# STM32L4x2 register map
File version: 1.6
CPU: CM4 r1p0, little endian, no MPU, no FPU, 3 interrupt priority bits
Registers are 32-bit, read-write, reset 0x0 unless marked. A register's access mark holds for its fields unless they carry their own. Offsets are from the block's base; [hi:lo] are bit positions; {n}, {i} and the like mark numbered series.

## WWDG — System window watchdog
Base 0x40002C00
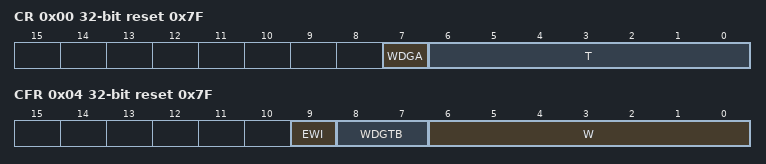
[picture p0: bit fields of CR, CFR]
0x00 CR reset 0x7F — Control register
  [7] WDGA — Activation bit
  [6:0] T — 7-bit counter (MSB to LSB)
0x04 CFR reset 0x7F — Configuration register
  [9] EWI — Early wakeup interrupt
  [8:7] WDGTB — Timer base
  [6:0] W — 7-bit window value
0x08 SR — Status register
  [0] EWIF — Early wakeup interrupt flag

## COMP — Comparator
Base 0x40010200
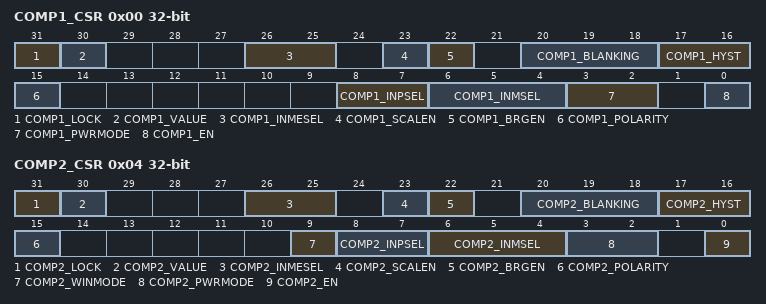
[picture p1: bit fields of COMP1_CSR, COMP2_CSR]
0x00 COMP1_CSR access per field — Comparator 1 control and status register
  [31] COMP1_LOCK wo — COMP1_CSR register lock bit
  [30] COMP1_VALUE ro — Comparator 1 output status bit
  [26:25] COMP1_INMESEL rw — comparator 1 input minus extended selection bits
  [23] COMP1_SCALEN rw — Voltage scaler enable bit
  [22] COMP1_BRGEN rw — Scaler bridge enable
  [20:18] COMP1_BLANKING rw — Comparator 1 blanking source selection bits
  [17:16] COMP1_HYST rw — Comparator 1 hysteresis selection bits
  [15] COMP1_POLARITY rw — Comparator 1 polarity selection bit
  [8:7] COMP1_INPSEL rw — Comparator1 input plus selection bit
  [6:4] COMP1_INMSEL rw — Comparator 1 Input Minus connection configuration bit
  [3:2] COMP1_PWRMODE rw — Power Mode of the comparator 1
  [0] COMP1_EN rw — Comparator 1 enable bit
0x04 COMP2_CSR access per field — Comparator 2 control and status register
  [31] COMP2_LOCK wo — COMP2_CSR register lock bit
  [30] COMP2_VALUE ro — Comparator 2 output status bit
  [26:25] COMP2_INMESEL rw — comparator 2 input minus extended selection bits
  [23] COMP2_SCALEN rw — Voltage scaler enable bit
  [22] COMP2_BRGEN rw — Scaler bridge enable
  [20:18] COMP2_BLANKING rw — Comparator 2 blanking source selection bits
  [17:16] COMP2_HYST rw — Comparator 2 hysteresis selection bits
  [15] COMP2_POLARITY rw — Comparator 2 polarity selection bit
  [9] COMP2_WINMODE rw — Windows mode selection bit
  [8:7] COMP2_INPSEL rw — Comparator 2 Input Plus connection configuration bit
  [6:4] COMP2_INMSEL rw — Comparator 2 Input Minus connection configuration bit
  [3:2] COMP2_PWRMODE rw — Power Mode of the comparator 2
  [0] COMP2_EN rw — Comparator 2 enable bit

## FIREWALL
Base 0x40011C00
0x00 CSSA — Code segment start address
  [23:8] ADD — code segment start address
0x04 CSL — Code segment length
  [21:8] LENG — code segment length
0x08 NVDSSA — Non-volatile data segment start address
  [23:8] ADD
0x0C NVDSL — Non-volatile data segment length
  [21:8] LENG
0x10 VDSSA — Volatile data segment start address
  [15:6] ADD
0x14 VDSL — Volatile data segment length
  [15:6] LENG — Non-volatile data segment length
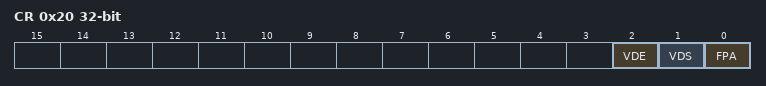
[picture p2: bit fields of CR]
0x20 CR — Configuration register
  [2] VDE — Volatile data execution
  [1] VDS — Volatile data shared
  [0] FPA — Firewall pre alarm

## SYSCFG — System configuration controller
Base 0x40010000
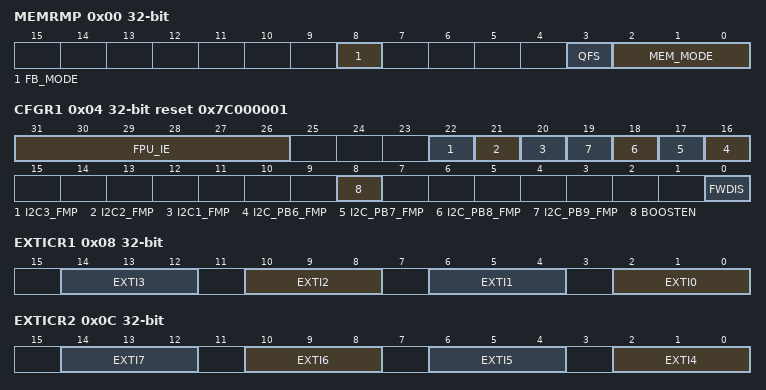
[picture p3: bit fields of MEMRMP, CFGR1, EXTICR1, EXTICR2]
0x00 MEMRMP — memory remap register
  [8] FB_MODE — Flash Bank mode selection
  [3] QFS — QUADSPI memory mapping swap
  [2:0] MEM_MODE — Memory mapping selection
0x04 CFGR1 reset 0x7C000001 — configuration register 1
  [31:26] FPU_IE — Floating Point Unit interrupts enable bits
  [22] I2C3_FMP — I2C3 Fast-mode Plus driving capability activation
  [21] I2C2_FMP — I2C2 Fast-mode Plus driving capability activation
  [20] I2C1_FMP — I2C1 Fast-mode Plus driving capability activation
  [n+10] I2C_PB{n}_FMP (n=6..9) — Fast-mode Plus (Fm+) driving capability activation on PB{n}
  [8] BOOSTEN — I/O analog switch voltage booster enable
  [0] FWDIS — Firewall disable
0x08 EXTICR1 — external interrupt configuration register 1
  [4n+2:4n] EXTI{n} (n=0..3) — EXTI {n} configuration bits
0x0C EXTICR2 — external interrupt configuration register 2
  [4n-14:4n-16] EXTI{n} (n=4..7) — EXTI {n} configuration bits
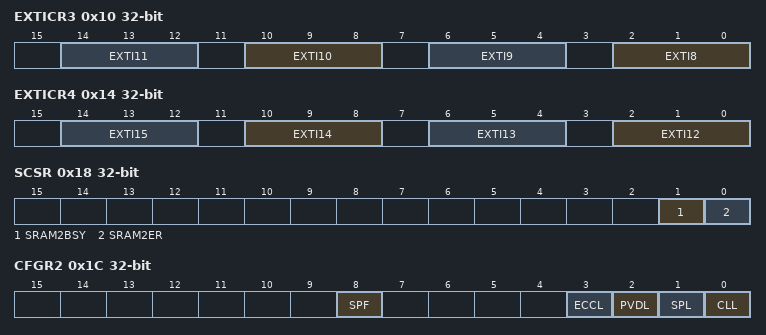
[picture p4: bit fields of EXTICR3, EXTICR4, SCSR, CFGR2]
0x10 EXTICR3 — external interrupt configuration register 3
  [4n-30:4n-32] EXTI{n} (n=8..11) — EXTI {n} configuration bits
0x14 EXTICR4 — external interrupt configuration register 4
  [4n-46:4n-48] EXTI{n} (n=12..15) — EXTI{n} configuration bits
0x18 SCSR access per field
  [1] SRAM2BSY ro — SRAM2 busy by erase operation
  [0] SRAM2ER rw — SRAM2 Erase
0x1C CFGR2 access per field
  [8] SPF rw — SRAM2 parity error flag
  [3] ECCL wo — ECC Lock
  [2] PVDL wo — PVD lock enable bit
  [1] SPL wo — SRAM2 parity lock bit
  [0] CLL wo — OCKUP (Hardfault) output enable bit
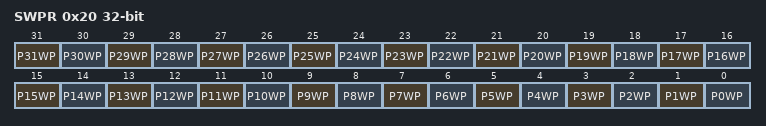
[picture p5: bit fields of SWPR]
0x20 SWPR wo
  [31] P31WP — SRAM2 page 31 write protection
  [n] P{n}WP (n=0..30)
0x24 SKR wo
  [7:0] KEY — SRAM2 write protection key for software erase
